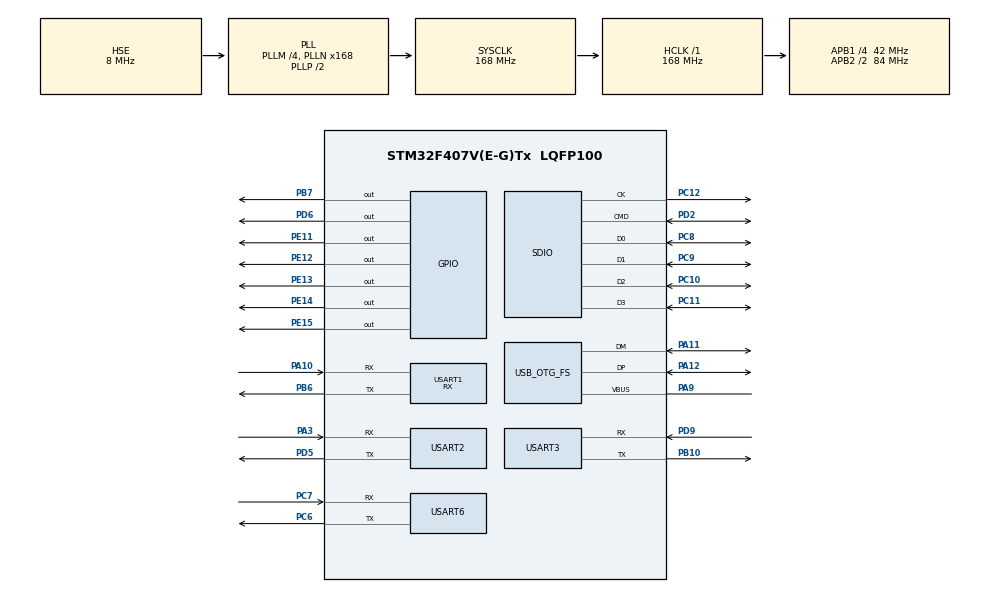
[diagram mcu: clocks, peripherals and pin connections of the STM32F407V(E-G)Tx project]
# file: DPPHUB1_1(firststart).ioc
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Dma.Request0=USART3_TX
Dma.Request1=SDIO_RX
Dma.Request2=SDIO_TX
Dma.Request3=USART2_TX
Dma.Request4=USART2_RX
Dma.Request5=USART1_RX
Dma.SDIO_RX.1.Direction=DMA_PERIPH_TO_MEMORY
Dma.SDIO_RX.1.FIFOMode=DMA_FIFOMODE_ENABLE
Dma.SDIO_RX.1.FIFOThreshold=DMA_FIFO_THRESHOLD_FULL
Dma.SDIO_RX.1.Instance=DMA2_Stream3
Dma.SDIO_RX.1.MemBurst=DMA_MBURST_INC4
Dma.SDIO_RX.1.MemDataAlignment=DMA_MDATAALIGN_WORD
Dma.SDIO_RX.1.MemInc=DMA_MINC_ENABLE
Dma.SDIO_RX.1.Mode=DMA_PFCTRL
Dma.SDIO_RX.1.PeriphBurst=DMA_PBURST_INC4
Dma.SDIO_RX.1.PeriphDataAlignment=DMA_PDATAALIGN_WORD
Dma.SDIO_RX.1.PeriphInc=DMA_PINC_DISABLE
Dma.SDIO_RX.1.Priority=DMA_PRIORITY_HIGH
Dma.SDIO_TX.2.Direction=DMA_MEMORY_TO_PERIPH
Dma.SDIO_TX.2.FIFOMode=DMA_FIFOMODE_ENABLE
Dma.SDIO_TX.2.FIFOThreshold=DMA_FIFO_THRESHOLD_FULL
Dma.SDIO_TX.2.Instance=DMA2_Stream6
Dma.SDIO_TX.2.MemBurst=DMA_MBURST_INC4
Dma.SDIO_TX.2.MemDataAlignment=DMA_MDATAALIGN_WORD
Dma.SDIO_TX.2.MemInc=DMA_MINC_ENABLE
Dma.SDIO_TX.2.Mode=DMA_PFCTRL
Dma.SDIO_TX.2.PeriphBurst=DMA_PBURST_INC4
Dma.SDIO_TX.2.PeriphDataAlignment=DMA_PDATAALIGN_WORD
Dma.SDIO_TX.2.PeriphInc=DMA_PINC_DISABLE
Dma.SDIO_TX.2.Priority=DMA_PRIORITY_HIGH
Dma.USART1_RX.5.Direction=DMA_PERIPH_TO_MEMORY
Dma.USART1_RX.5.FIFOMode=DMA_FIFOMODE_DISABLE
Dma.USART1_RX.5.Instance=DMA2_Stream2
Dma.USART1_RX.5.MemDataAlignment=DMA_MDATAALIGN_BYTE
Dma.USART1_RX.5.MemInc=DMA_MINC_ENABLE
Dma.USART1_RX.5.Mode=DMA_CIRCULAR
Dma.USART1_RX.5.PeriphDataAlignment=DMA_PDATAALIGN_BYTE
Dma.USART1_RX.5.PeriphInc=DMA_PINC_DISABLE
Dma.USART1_RX.5.Priority=DMA_PRIORITY_VERY_HIGH
Dma.USART2_RX.4.Direction=DMA_PERIPH_TO_MEMORY
Dma.USART2_RX.4.FIFOMode=DMA_FIFOMODE_DISABLE
Dma.USART2_RX.4.Instance=DMA1_Stream5
Dma.USART2_RX.4.MemDataAlignment=DMA_MDATAALIGN_BYTE
Dma.USART2_RX.4.MemInc=DMA_MINC_ENABLE
Dma.USART2_RX.4.Mode=DMA_CIRCULAR
Dma.USART2_RX.4.PeriphDataAlignment=DMA_PDATAALIGN_BYTE
Dma.USART2_RX.4.PeriphInc=DMA_PINC_DISABLE
Dma.USART2_RX.4.Priority=DMA_PRIORITY_LOW
Dma.USART2_TX.3.Direction=DMA_MEMORY_TO_PERIPH
Dma.USART2_TX.3.FIFOMode=DMA_FIFOMODE_DISABLE
Dma.USART2_TX.3.Instance=DMA1_Stream6
Dma.USART2_TX.3.MemDataAlignment=DMA_MDATAALIGN_BYTE
Dma.USART2_TX.3.MemInc=DMA_MINC_ENABLE
Dma.USART2_TX.3.Mode=DMA_NORMAL
Dma.USART2_TX.3.PeriphDataAlignment=DMA_PDATAALIGN_BYTE
Dma.USART2_TX.3.PeriphInc=DMA_PINC_DISABLE
Dma.USART2_TX.3.Priority=DMA_PRIORITY_LOW
Dma.USART3_TX.0.Direction=DMA_MEMORY_TO_PERIPH
Dma.USART3_TX.0.FIFOMode=DMA_FIFOMODE_DISABLE
Dma.USART3_TX.0.Instance=DMA1_Stream3
Dma.USART3_TX.0.MemDataAlignment=DMA_MDATAALIGN_BYTE
Dma.USART3_TX.0.MemInc=DMA_MINC_ENABLE
Dma.USART3_TX.0.Mode=DMA_NORMAL
Dma.USART3_TX.0.PeriphDataAlignment=DMA_PDATAALIGN_BYTE
Dma.USART3_TX.0.PeriphInc=DMA_PINC_DISABLE
Dma.USART3_TX.0.Priority=DMA_PRIORITY_VERY_HIGH
FATFS.USE_DMA_CODE_SD=1
FATFS._USE_LFN=1
Mcu.Family=STM32F4
Mcu.Name=STM32F407V(E-G)Tx
Mcu.Package=LQFP100
NVIC.DMA1_Stream3_IRQn=true\:0\:0\:false\:false\:true\:false
NVIC.DMA1_Stream5_IRQn=true\:0\:0\:false\:false\:true\:false
NVIC.DMA1_Stream6_IRQn=true\:0\:0\:false\:false\:true\:false
NVIC.DMA2_Stream2_IRQn=true\:0\:0\:false\:false\:true\:false
NVIC.DMA2_Stream3_IRQn=true\:0\:0\:false\:false\:true\:false
NVIC.DMA2_Stream6_IRQn=true\:0\:0\:false\:false\:true\:false
NVIC.OTG_FS_IRQn=true\:0\:0\:false\:false\:true\:true
NVIC.PriorityGroup=NVIC_PRIORITYGROUP_4
NVIC.SDIO_IRQn=true\:0\:0\:false\:false\:true\:true
NVIC.USART2_IRQn=true\:0\:0\:false\:false\:true\:true
NVIC.USART3_IRQn=true\:0\:0\:false\:false\:true\:true
NVIC.USART6_IRQn=true\:0\:0\:false\:false\:true\:true
PA10.Mode=Asynchronous
PA10.Signal=USART1_RX
PA11.Mode=Device_Only
PA11.Signal=USB_OTG_FS_DM
PA12.Mode=Device_Only
PA12.Signal=USB_OTG_FS_DP
PA3.Mode=Asynchronous
PA3.Signal=USART2_RX
PA9.Mode=Activate_VBUS
PA9.Signal=USB_OTG_FS_VBUS
PB10.Mode=Asynchronous
PB10.Signal=USART3_TX
PB6.Mode=Asynchronous
PB6.Signal=USART1_TX
PB7.Signal=GPIO_Output
PC10.Mode=SD_4_bits_Wide_bus
PC10.Signal=SDIO_D2
PC11.Mode=SD_4_bits_Wide_bus
PC11.Signal=SDIO_D3
PC12.Mode=SD_4_bits_Wide_bus
PC12.Signal=SDIO_CK
PC6.Mode=Asynchronous
PC6.Signal=USART6_TX
PC7.Mode=Asynchronous
PC7.Signal=USART6_RX
PC8.Mode=SD_4_bits_Wide_bus
PC8.Signal=SDIO_D0
PC9.Mode=SD_4_bits_Wide_bus
PC9.Signal=SDIO_D1
PD0.Signal=CAN1_RX
PD1.Signal=CAN1_TX
PD2.Mode=SD_4_bits_Wide_bus
PD2.Signal=SDIO_CMD
PD5.Mode=Asynchronous
PD5.Signal=USART2_TX
PD6.GPIO_ModeDefaultOutputPP=GPIO_MODE_OUTPUT_PP
PD6.GPIO_PuPd=GPIO_PULLUP
PD6.GPIO_Speed=GPIO_SPEED_FREQ_VERY_HIGH
PD6.PinState=GPIO_PIN_SET
PD6.Signal=GPIO_Output
PD9.Mode=Asynchronous
PD9.Signal=USART3_RX
PE11.GPIO_Speed=GPIO_SPEED_FREQ_VERY_HIGH
PE11.Signal=GPIO_Output
PE12.GPIO_Speed=GPIO_SPEED_FREQ_VERY_HIGH
PE12.Signal=GPIO_Output
PE13.GPIO_Speed=GPIO_SPEED_FREQ_VERY_HIGH
PE13.Signal=GPIO_Output
PE14.GPIO_Speed=GPIO_SPEED_FREQ_VERY_HIGH
PE14.Signal=GPIO_Output
PE15.GPIO_Speed=GPIO_SPEED_FREQ_VERY_HIGH
PE15.Signal=GPIO_Output
PH0-OSC_IN.Mode=HSE-External-Oscillator
PH0-OSC_IN.Signal=RCC_OSC_IN
PH1-OSC_OUT.Mode=HSE-External-Oscillator
PH1-OSC_OUT.Signal=RCC_OSC_OUT
ProjectManager.HeapSize=0x2000
ProjectManager.StackSize=0x4000
ProjectManager.TargetToolchain=SW4STM32
RCC.48MHZClocksFreq_Value=48000000
RCC.AHBFreq_Value=168000000
RCC.APB1CLKDivider=RCC_HCLK_DIV4
RCC.APB1Freq_Value=42000000
RCC.APB1TimFreq_Value=84000000
RCC.APB2CLKDivider=RCC_HCLK_DIV2
RCC.APB2Freq_Value=84000000
RCC.APB2TimFreq_Value=168000000
RCC.CortexFreq_Value=168000000
RCC.HCLKFreq_Value=168000000
RCC.HSE_VALUE=8000000
RCC.HSI_VALUE=16000000
RCC.LSE_VALUE=32768
RCC.PLLM=4
RCC.PLLN=168
RCC.PLLQ=7
RCC.RCC_RTC_Clock_SourceVirtual=RCC_RTCCLKSOURCE_HSE_DIV16
RCC.RCC_RTC_Clock_Source_FROM_HSE=RCC_RTCCLKSOURCE_HSE_DIV16
RCC.SYSCLKFreq_VALUE=168000000
RCC.SYSCLKSource=RCC_SYSCLKSOURCE_PLLCLK
RCC.VCOOutputFreq_Value=336000000
RTC.AsynchPrediv=49
RTC.Date=4
RTC.Hours=10
RTC.Minutes=20
RTC.Month=RTC_MONTH_JULY
RTC.SynchPrediv=9999
RTC.Year=19
SDIO.ClockDiv=10
USART1.Mode=MODE_RX
USART1.Parity=PARITY_EVEN
USART1.VirtualMode=VM_ASYNC
USART1.WordLength=WORDLENGTH_9B
USART2.VirtualMode=VM_ASYNC
USART3.VirtualMode=VM_ASYNC
USART6.VirtualMode=VM_ASYNC
USB_DEVICE.CLASS_NAME_FS=CDC
USB_DEVICE.MANUFACTURER_STRING-CDC_FS=DPP_HUB1
USB_DEVICE.PRODUCT_STRING_CDC_FS=DPP_HUB1 Virtual ComPort
USB_DEVICE.VirtualMode-CDC_FS=Cdc
USB_DEVICE.VirtualModeFS=Cdc_FS
USB_OTG_FS.VirtualMode=Device_Only
VP_FATFS_VS_SDIO.Mode=SDIO
VP_RTC_VS_RTC_Activate.Mode=RTC_Enabled
VP_RTC_VS_RTC_Calendar.Mode=RTC_Calendar
VP_USB_DEVICE_VS_USB_DEVICE_CDC_FS.Mode=CDC_FS
board=custom

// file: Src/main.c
/* USER CODE BEGIN Header */
/**
  ******************************************************************************
  * @file           : main.c
  * @brief          : Main program body
  ******************************************************************************
  ** This notice applies to any and all portions of this file
  * that are not between comment pairs USER CODE BEGIN and
  * USER CODE END. Other portions of this file, whether
  * inserted by the user or by software development tools
  * are owned by their respective copyright owners.
  *
  * COPYRIGHT(c) 2019 STMicroelectronics
  *
  * Redistribution and use in source and binary forms, with or without modification,
  * are permitted provided that the following conditions are met:
  *   1. Redistributions of source code must retain the above copyright notice,
  *      this list of conditions and the following disclaimer.
  *   2. Redistributions in binary form must reproduce the above copyright notice,
  *      this list of conditions and the following disclaimer in the documentation
  *      and/or other materials provided with the distribution.
  *   3. Neither the name of STMicroelectronics nor the names of its contributors
  *      may be used to endorse or promote products derived from this software
  *      without specific prior written permission.
  *
  * THIS SOFTWARE IS PROVIDED BY THE COPYRIGHT HOLDERS AND CONTRIBUTORS "AS IS"
  * AND ANY EXPRESS OR IMPLIED WARRANTIES, INCLUDING, BUT NOT LIMITED TO, THE
  * IMPLIED WARRANTIES OF MERCHANTABILITY AND FITNESS FOR A PARTICULAR PURPOSE ARE
  * DISCLAIMED. IN NO EVENT SHALL THE COPYRIGHT HOLDER OR CONTRIBUTORS BE LIABLE
  * FOR ANY DIRECT, INDIRECT, INCIDENTAL, SPECIAL, EXEMPLARY, OR CONSEQUENTIAL
  * DAMAGES (INCLUDING, BUT NOT LIMITED TO, PROCUREMENT OF SUBSTITUTE GOODS OR
  * SERVICES; LOSS OF USE, DATA, OR PROFITS; OR BUSINESS INTERRUPTION) HOWEVER
  * CAUSED AND ON ANY THEORY OF LIABILITY, WHETHER IN CONTRACT, STRICT LIABILITY,
  * OR TORT (INCLUDING NEGLIGENCE OR OTHERWISE) ARISING IN ANY WAY OUT OF THE USE
  * OF THIS SOFTWARE, EVEN IF ADVISED OF THE POSSIBILITY OF SUCH DAMAGE.
  *
  ******************************************************************************
  */
/* USER CODE END Header */

#include "main.h"
#include "fatfs.h"
#include "usb_device.h"

RTC_HandleTypeDef hrtc;

SD_HandleTypeDef hsd;
DMA_HandleTypeDef hdma_sdio_rx;
DMA_HandleTypeDef hdma_sdio_tx;

UART_HandleTypeDef huart1;
UART_HandleTypeDef huart2;
UART_HandleTypeDef huart3;
UART_HandleTypeDef huart6;
DMA_HandleTypeDef hdma_usart1_rx;
DMA_HandleTypeDef hdma_usart2_tx;
DMA_HandleTypeDef hdma_usart2_rx;
DMA_HandleTypeDef hdma_usart3_tx;

void SystemClock_Config(void);
static void MX_GPIO_Init(void);
static void MX_DMA_Init(void);
static void MX_USART3_UART_Init(void);
static void MX_USART6_UART_Init(void);
static void MX_RTC_Init(void);
static void MX_SDIO_SD_Init(void);
static void MX_USART2_UART_Init(void);
static void MX_USART1_UART_Init(void);

int main(void)
{

  /* MCU Configuration--------------------------------------------------------*/

  /* Reset of all peripherals, Initializes the Flash interface and the Systick. */
  HAL_Init();

  /* Configure the system clock */
  SystemClock_Config();

  /* Initialize all configured peripherals */
  MX_GPIO_Init();
  MX_DMA_Init();
  MX_USART3_UART_Init();
  MX_USART6_UART_Init();
  MX_USB_DEVICE_Init();
  MX_RTC_Init();
  MX_SDIO_SD_Init();
  MX_FATFS_Init();
  MX_USART2_UART_Init();
  MX_USART1_UART_Init();
  /* USER CODE BEGIN 2 */
  HAL_GPIO_WritePin(GPIOB, GPIO_PIN_7, DISABLE);
  HAL_GPIO_WritePin(GPIOD, GPIO_PIN_6, DISABLE);
  sd_ini();
//  start_ra_receiving(RA_huart);
//  start_dpp_receiving(HSOW_huart);

  /* USER CODE END 2 */

  /* Infinite loop */
  /* USER CODE BEGIN WHILE */
  while (1)
  {
	  sensor_cmd_handler();
	  way_code_handler();
	  RA_handler();

//		HAL_GPIO_TogglePin(GPIOE, GPIO_PIN_12);
//		HAL_Delay(100);
//		HAL_GPIO_TogglePin(GPIOE, GPIO_PIN_13);
//		HAL_Delay(100);
//		HAL_GPIO_TogglePin(GPIOE, GPIO_PIN_14);
//		HAL_Delay(100);
//		HAL_GPIO_TogglePin(GPIOE, GPIO_PIN_15);
//		HAL_Delay(100);

    /* USER CODE END WHILE */

  }
}

void SystemClock_Config(void)
{
  RCC_OscInitTypeDef RCC_OscInitStruct = {0};
  RCC_ClkInitTypeDef RCC_ClkInitStruct = {0};
  RCC_PeriphCLKInitTypeDef PeriphClkInitStruct = {0};

  /**Configure the main internal regulator output voltage
  */
  __HAL_RCC_PWR_CLK_ENABLE();
  __HAL_PWR_VOLTAGESCALING_CONFIG(PWR_REGULATOR_VOLTAGE_SCALE1);
  /**Initializes the CPU, AHB and APB busses clocks
  */
  RCC_OscInitStruct.OscillatorType = RCC_OSCILLATORTYPE_HSE;
  RCC_OscInitStruct.HSEState = RCC_HSE_ON;
  RCC_OscInitStruct.PLL.PLLState = RCC_PLL_ON;
  RCC_OscInitStruct.PLL.PLLSource = RCC_PLLSOURCE_HSE;
  RCC_OscInitStruct.PLL.PLLM = 4;
  RCC_OscInitStruct.PLL.PLLN = 168;
  RCC_OscInitStruct.PLL.PLLP = RCC_PLLP_DIV2;
  RCC_OscInitStruct.PLL.PLLQ = 7;
  if (HAL_RCC_OscConfig(&RCC_OscInitStruct) != HAL_OK)
  {
    Error_Handler();
  }
  /**Initializes the CPU, AHB and APB busses clocks
  */
  RCC_ClkInitStruct.ClockType = RCC_CLOCKTYPE_HCLK|RCC_CLOCKTYPE_SYSCLK
                              |RCC_CLOCKTYPE_PCLK1|RCC_CLOCKTYPE_PCLK2;
  RCC_ClkInitStruct.SYSCLKSource = RCC_SYSCLKSOURCE_PLLCLK;
  RCC_ClkInitStruct.AHBCLKDivider = RCC_SYSCLK_DIV1;
  RCC_ClkInitStruct.APB1CLKDivider = RCC_HCLK_DIV4;
  RCC_ClkInitStruct.APB2CLKDivider = RCC_HCLK_DIV2;

  if (HAL_RCC_ClockConfig(&RCC_ClkInitStruct, FLASH_LATENCY_5) != HAL_OK)
  {
    Error_Handler();
  }
  PeriphClkInitStruct.PeriphClockSelection = RCC_PERIPHCLK_RTC;
  PeriphClkInitStruct.RTCClockSelection = RCC_RTCCLKSOURCE_HSE_DIV16;
  if (HAL_RCCEx_PeriphCLKConfig(&PeriphClkInitStruct) != HAL_OK)
  {
    Error_Handler();
  }
}

static void MX_RTC_Init(void)
{

  RTC_TimeTypeDef sTime = {0};
  RTC_DateTypeDef sDate = {0};

  /**Initialize RTC Only
  */
  hrtc.Instance = RTC;
  hrtc.Init.HourFormat = RTC_HOURFORMAT_24;
  hrtc.Init.AsynchPrediv = 49;
  hrtc.Init.SynchPrediv = 9999;
  hrtc.Init.OutPut = RTC_OUTPUT_DISABLE;
  hrtc.Init.OutPutPolarity = RTC_OUTPUT_POLARITY_HIGH;
  hrtc.Init.OutPutType = RTC_OUTPUT_TYPE_OPENDRAIN;
  if (HAL_RTC_Init(&hrtc) != HAL_OK)
  {
    Error_Handler();
  }

  /**Initialize RTC and set the Time and Date
  */
  sTime.Hours = 0x10;
  sTime.Minutes = 0x20;
  sTime.Seconds = 0x0;
  sTime.DayLightSaving = RTC_DAYLIGHTSAVING_NONE;
  sTime.StoreOperation = RTC_STOREOPERATION_RESET;
  if (HAL_RTC_SetTime(&hrtc, &sTime, RTC_FORMAT_BCD) != HAL_OK)
  {
    Error_Handler();
  }
  sDate.WeekDay = RTC_WEEKDAY_MONDAY;
  sDate.Month = RTC_MONTH_JULY;
  sDate.Date = 0x4;
  sDate.Year = 0x19;

  if (HAL_RTC_SetDate(&hrtc, &sDate, RTC_FORMAT_BCD) != HAL_OK)
  {
    Error_Handler();
  }

}

static void MX_SDIO_SD_Init(void)
{

  hsd.Instance = SDIO;
  hsd.Init.ClockEdge = SDIO_CLOCK_EDGE_RISING;
  hsd.Init.ClockBypass = SDIO_CLOCK_BYPASS_DISABLE;
  hsd.Init.ClockPowerSave = SDIO_CLOCK_POWER_SAVE_DISABLE;
  hsd.Init.BusWide = SDIO_BUS_WIDE_1B;
  hsd.Init.HardwareFlowControl = SDIO_HARDWARE_FLOW_CONTROL_DISABLE;
  hsd.Init.ClockDiv = 10;

}

static void MX_USART1_UART_Init(void)
{

  huart1.Instance = USART1;
  huart1.Init.BaudRate = 115200;
  huart1.Init.WordLength = UART_WORDLENGTH_9B;
  huart1.Init.StopBits = UART_STOPBITS_1;
  huart1.Init.Parity = UART_PARITY_EVEN;
  huart1.Init.Mode = UART_MODE_RX;
  huart1.Init.HwFlowCtl = UART_HWCONTROL_NONE;
  huart1.Init.OverSampling = UART_OVERSAMPLING_16;
  if (HAL_UART_Init(&huart1) != HAL_OK)
  {
    Error_Handler();
  }

}

static void MX_USART2_UART_Init(void)
{

  huart2.Instance = USART2;
  huart2.Init.BaudRate = 115200;
  huart2.Init.WordLength = UART_WORDLENGTH_8B;
  huart2.Init.StopBits = UART_STOPBITS_1;
  huart2.Init.Parity = UART_PARITY_NONE;
  huart2.Init.Mode = UART_MODE_TX_RX;
  huart2.Init.HwFlowCtl = UART_HWCONTROL_NONE;
  huart2.Init.OverSampling = UART_OVERSAMPLING_16;
  if (HAL_UART_Init(&huart2) != HAL_OK)
  {
    Error_Handler();
  }

}

static void MX_USART3_UART_Init(void)
{

  huart3.Instance = USART3;
  huart3.Init.BaudRate = 115200;
  huart3.Init.WordLength = UART_WORDLENGTH_8B;
  huart3.Init.StopBits = UART_STOPBITS_1;
  huart3.Init.Parity = UART_PARITY_NONE;
  huart3.Init.Mode = UART_MODE_TX_RX;
  huart3.Init.HwFlowCtl = UART_HWCONTROL_NONE;
  huart3.Init.OverSampling = UART_OVERSAMPLING_16;
  if (HAL_UART_Init(&huart3) != HAL_OK)
  {
    Error_Handler();
  }

}

static void MX_USART6_UART_Init(void)
{

  huart6.Instance = USART6;
  huart6.Init.BaudRate = 115200;
  huart6.Init.WordLength = UART_WORDLENGTH_8B;
  huart6.Init.StopBits = UART_STOPBITS_1;
  huart6.Init.Parity = UART_PARITY_NONE;
  huart6.Init.Mode = UART_MODE_TX_RX;
  huart6.Init.HwFlowCtl = UART_HWCONTROL_NONE;
  huart6.Init.OverSampling = UART_OVERSAMPLING_16;
  if (HAL_UART_Init(&huart6) != HAL_OK)
  {
    Error_Handler();
  }

}

static void MX_DMA_Init(void)
{
  /* DMA controller clock enable */
  __HAL_RCC_DMA1_CLK_ENABLE();
  __HAL_RCC_DMA2_CLK_ENABLE();

  /* DMA interrupt init */
  /* DMA1_Stream3_IRQn interrupt configuration */
  HAL_NVIC_SetPriority(DMA1_Stream3_IRQn, 0, 0);
  HAL_NVIC_EnableIRQ(DMA1_Stream3_IRQn);
  /* DMA1_Stream5_IRQn interrupt configuration */
  HAL_NVIC_SetPriority(DMA1_Stream5_IRQn, 0, 0);
  HAL_NVIC_EnableIRQ(DMA1_Stream5_IRQn);
  /* DMA1_Stream6_IRQn interrupt configuration */
  HAL_NVIC_SetPriority(DMA1_Stream6_IRQn, 0, 0);
  HAL_NVIC_EnableIRQ(DMA1_Stream6_IRQn);
  /* DMA2_Stream2_IRQn interrupt configuration */
  HAL_NVIC_SetPriority(DMA2_Stream2_IRQn, 0, 0);
  HAL_NVIC_EnableIRQ(DMA2_Stream2_IRQn);
  /* DMA2_Stream3_IRQn interrupt configuration */
  HAL_NVIC_SetPriority(DMA2_Stream3_IRQn, 0, 0);
  HAL_NVIC_EnableIRQ(DMA2_Stream3_IRQn);
  /* DMA2_Stream6_IRQn interrupt configuration */
  HAL_NVIC_SetPriority(DMA2_Stream6_IRQn, 0, 0);
  HAL_NVIC_EnableIRQ(DMA2_Stream6_IRQn);

}

static void MX_GPIO_Init(void)
{
  GPIO_InitTypeDef GPIO_InitStruct = {0};

  /* GPIO Ports Clock Enable */
  __HAL_RCC_GPIOH_CLK_ENABLE();
  __HAL_RCC_GPIOA_CLK_ENABLE();
  __HAL_RCC_GPIOE_CLK_ENABLE();
  __HAL_RCC_GPIOB_CLK_ENABLE();
  __HAL_RCC_GPIOD_CLK_ENABLE();
  __HAL_RCC_GPIOC_CLK_ENABLE();

  /*Configure GPIO pin Output Level */
  HAL_GPIO_WritePin(GPIOE, GPIO_PIN_11|GPIO_PIN_12|GPIO_PIN_13|GPIO_PIN_14
                          |GPIO_PIN_15, GPIO_PIN_RESET);

  /*Configure GPIO pin Output Level */
  HAL_GPIO_WritePin(GPIOD, GPIO_PIN_6, GPIO_PIN_SET);

  /*Configure GPIO pin Output Level */
  HAL_GPIO_WritePin(GPIOB, GPIO_PIN_7, GPIO_PIN_RESET);

  /*Configure GPIO pins : PE11 PE12 PE13 PE14
                           PE15 */
  GPIO_InitStruct.Pin = GPIO_PIN_11|GPIO_PIN_12|GPIO_PIN_13|GPIO_PIN_14
                          |GPIO_PIN_15;
  GPIO_InitStruct.Mode = GPIO_MODE_OUTPUT_PP;
  GPIO_InitStruct.Pull = GPIO_NOPULL;
  GPIO_InitStruct.Speed = GPIO_SPEED_FREQ_VERY_HIGH;
  HAL_GPIO_Init(GPIOE, &GPIO_InitStruct);

  /*Configure GPIO pins : PD0 PD1 */
  GPIO_InitStruct.Pin = GPIO_PIN_0|GPIO_PIN_1;
  GPIO_InitStruct.Mode = GPIO_MODE_AF_PP;
  GPIO_InitStruct.Pull = GPIO_NOPULL;
  GPIO_InitStruct.Speed = GPIO_SPEED_FREQ_VERY_HIGH;
  GPIO_InitStruct.Alternate = GPIO_AF9_CAN1;
  HAL_GPIO_Init(GPIOD, &GPIO_InitStruct);

  /*Configure GPIO pin : PD6 */
  GPIO_InitStruct.Pin = GPIO_PIN_6;
  GPIO_InitStruct.Mode = GPIO_MODE_OUTPUT_PP;
  GPIO_InitStruct.Pull = GPIO_PULLUP;
  GPIO_InitStruct.Speed = GPIO_SPEED_FREQ_VERY_HIGH;
  HAL_GPIO_Init(GPIOD, &GPIO_InitStruct);

  /*Configure GPIO pin : PB7 */
  GPIO_InitStruct.Pin = GPIO_PIN_7;
  GPIO_InitStruct.Mode = GPIO_MODE_OUTPUT_PP;
  GPIO_InitStruct.Pull = GPIO_NOPULL;
  GPIO_InitStruct.Speed = GPIO_SPEED_FREQ_LOW;
  HAL_GPIO_Init(GPIOB, &GPIO_InitStruct);

}

/* USER CODE BEGIN 4 */
UART_HandleTypeDef* Get_huart1_addr(void)
{
	return &huart1;
}
UART_HandleTypeDef* Get_huart2_addr(void)
{
	return &huart2;
}
UART_HandleTypeDef* Get_huart3_addr(void)
{
	return &huart3;
}
UART_HandleTypeDef* Get_huart6_addr(void)
{
	return &huart6;
}
/* USER CODE END 4 */

void Error_Handler(void)
{
}

/************************ (C) COPYRIGHT STMicroelectronics *****END OF FILE****/
